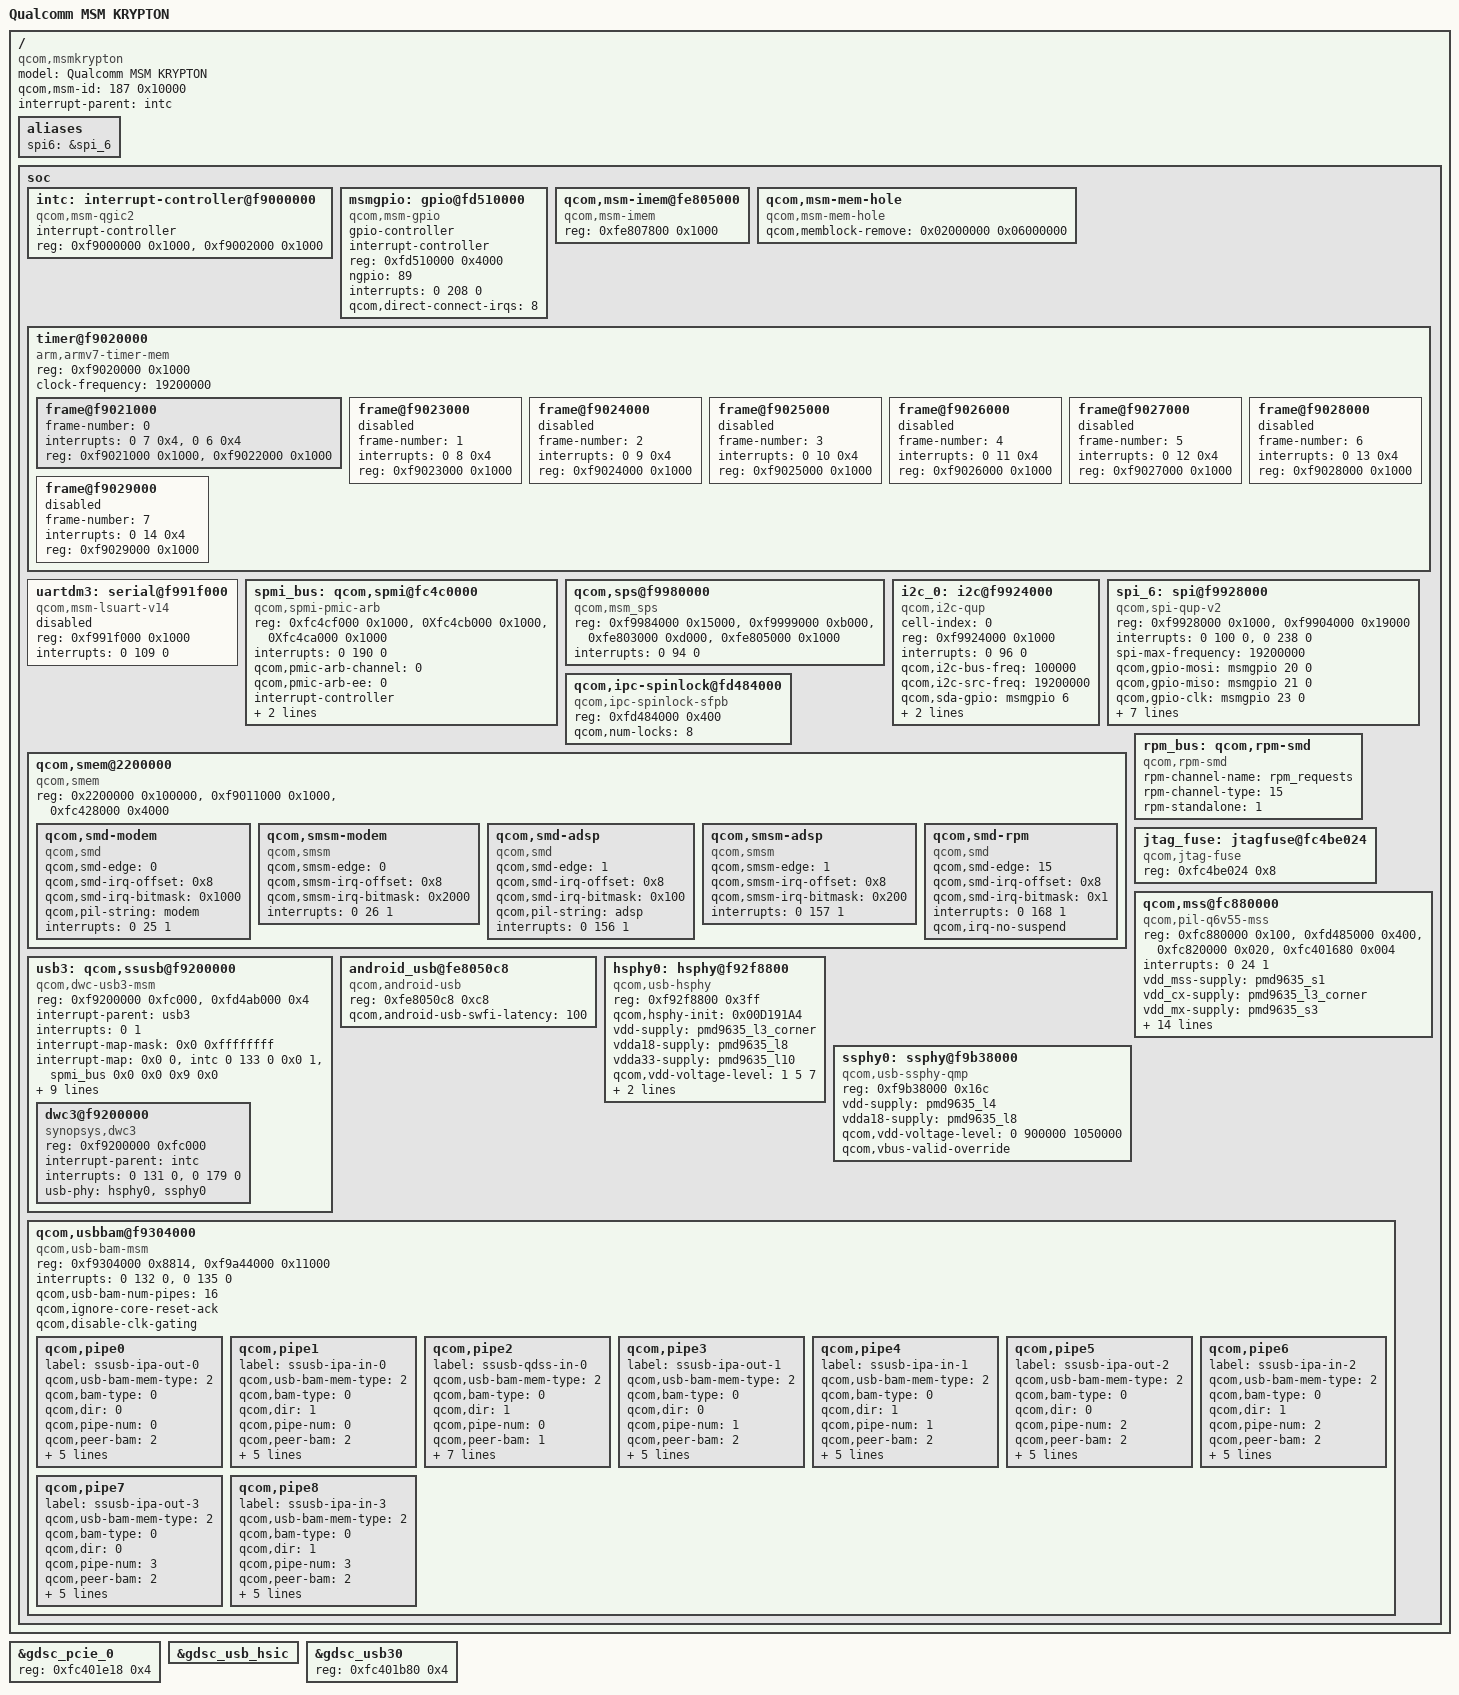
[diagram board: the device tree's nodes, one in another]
/* Copyright (c) 2013, The Linux Foundation. All rights reserved.
 *
 * This program is free software; you can redistribute it and/or modify
 * it under the terms of the GNU General Public License version 2 and
 * only version 2 as published by the Free Software Foundation.
 *
 * This program is distributed in the hope that it will be useful,
 * but WITHOUT ANY WARRANTY; without even the implied warranty of
 * MERCHANTABILITY or FITNESS FOR A PARTICULAR PURPOSE.  See the
 * GNU General Public License for more details.
 */

/include/ "skeleton.dtsi"

/ {
	model = "Qualcomm MSM KRYPTON";
	compatible = "qcom,msmkrypton";
	qcom,msm-id = <187 0x10000>;
	interrupt-parent = <&intc>;

	aliases {
		spi6 = &spi_6;
	};

	soc: soc { };
};

/include/ "msmkrypton-smp2p.dtsi"
/include/ "msmkrypton-coresight.dtsi"
/include/ "msm-gdsc.dtsi"

&soc {
	#address-cells = <1>;
	#size-cells = <1>;
	ranges;

	intc: interrupt-controller@f9000000 {
		compatible = "qcom,msm-qgic2";
		interrupt-controller;
		#interrupt-cells = <3>;
		reg = <0xf9000000 0x1000>,
		      <0xf9002000 0x1000>;
	};

	msmgpio: gpio@fd510000 {
		compatible = "qcom,msm-gpio";
		gpio-controller;
		#gpio-cells = <2>;
		interrupt-controller;
		#interrupt-cells = <2>;
		reg = <0xfd510000 0x4000>;
		ngpio = <89>;
		interrupts = <0 208 0>;
		qcom,direct-connect-irqs = <8>;
	};

	qcom,msm-imem@fe805000 {
		compatible = "qcom,msm-imem";
		reg = <0xfe807800 0x1000>; /* Address and size of IMEM */
	};

	qcom,msm-mem-hole {
		compatible = "qcom,msm-mem-hole";
		qcom,memblock-remove = <0x02000000 0x06000000>; /* Address and Size of Hole */
	};

	timer@f9020000 {
		#address-cells = <1>;
		#size-cells = <1>;
		ranges;
		compatible = "arm,armv7-timer-mem";
		reg = <0xf9020000 0x1000>;
		clock-frequency = <19200000>;

		frame@f9021000 {
			frame-number = <0>;
			interrupts = <0 7 0x4>,
				     <0 6 0x4>;
			reg = <0xf9021000 0x1000>,
			      <0xf9022000 0x1000>;
		};

		frame@f9023000 {
			frame-number = <1>;
			interrupts = <0 8 0x4>;
			reg = <0xf9023000 0x1000>;
			status = "disabled";
		};

		frame@f9024000 {
			frame-number = <2>;
			interrupts = <0 9 0x4>;
			reg = <0xf9024000 0x1000>;
			status = "disabled";
		};

		frame@f9025000 {
			frame-number = <3>;
			interrupts = <0 10 0x4>;
			reg = <0xf9025000 0x1000>;
			status = "disabled";
		};

		frame@f9026000 {
			frame-number = <4>;
			interrupts = <0 11 0x4>;
			reg = <0xf9026000 0x1000>;
			status = "disabled";
		};

		frame@f9027000 {
			frame-number = <5>;
			interrupts = <0 12 0x4>;
			reg = <0xf9027000 0x1000>;
			status = "disabled";
		};

		frame@f9028000 {
			frame-number = <6>;
			interrupts = <0 13 0x4>;
			reg = <0xf9028000 0x1000>;
			status = "disabled";
		};

		frame@f9029000 {
			frame-number = <7>;
			interrupts = <0 14 0x4>;
			reg = <0xf9029000 0x1000>;
			status = "disabled";
		};
	};

	uartdm3: serial@f991f000 {
		compatible = "qcom,msm-lsuart-v14";
		reg = <0xf991f000 0x1000>;
		interrupts = <0 109 0>;
		status = "disabled";
	};

	spmi_bus: qcom,spmi@fc4c0000 {
		compatible = "qcom,spmi-pmic-arb";
		reg = <0xfc4cf000 0x1000>,
		      <0Xfc4cb000 0x1000>,
		      <0Xfc4ca000 0x1000>;
		reg-names = "core", "intr", "cnfg";
		interrupts = <0 190 0>;
		qcom,pmic-arb-channel = <0>;
		qcom,pmic-arb-ee = <0>;
		#interrupt-cells = <3>;
		interrupt-controller;
		#address-cells = <1>;
		#size-cells = <0>;
		cell-index = <0>;
		qcom,not-wakeup; /* Needed until MPM is fully configured */
	};

	qcom,sps@f9980000 {
		compatible = "qcom,msm_sps";
		reg = <0xf9984000 0x15000>,
		      <0xf9999000 0xb000>,
		      <0xfe803000 0xd000>,
			  <0xfe805000 0x1000>;
		interrupts = <0 94 0>;
	};

	i2c_0: i2c@f9924000 { /* BLSP1 QUP2 */
		cell-index = <0>;
		compatible = "qcom,i2c-qup";
		#address-cells = <1>;
		#size-cells = <0>;
		reg-names = "qup_phys_addr";
		reg = <0xf9924000 0x1000>;
		interrupt-names = "qup_err_intr";
		interrupts = <0 96 0>;
		qcom,i2c-bus-freq = <100000>;
		qcom,i2c-src-freq = <19200000>;
		qcom,sda-gpio = <&msmgpio 6 0>;
		qcom,scl-gpio = <&msmgpio 7 0>;
		qcom,master-id = <86>;
	};

	spi_6: spi@f9928000 { /* BLSP1 QUP6 */
		compatible = "qcom,spi-qup-v2";
		#address-cells = <1>;
		#size-cells = <0>;
		reg-names = "spi_physical", "spi_bam_physical";
		reg = <0xf9928000 0x1000>,
		      <0xf9904000 0x19000>;
		interrupt-names = "spi_irq", "spi_bam_irq";
		interrupts = <0 100 0>, <0 238 0>;
		spi-max-frequency = <19200000>;

		qcom,gpio-mosi = <&msmgpio 20 0>;
		qcom,gpio-miso = <&msmgpio 21 0>;
		qcom,gpio-clk  = <&msmgpio 23 0>;
		qcom,gpio-cs0  = <&msmgpio 22 0>;

		qcom,infinite-mode = <0>;
		qcom,use-bam;
		qcom,ver-reg-exists;
		qcom,bam-consumer-pipe-index = <22>;
		qcom,bam-producer-pipe-index = <23>;
		qcom,master-id = <86>;
	};

	qcom,ipc-spinlock@fd484000 {
		compatible = "qcom,ipc-spinlock-sfpb";
		reg = <0xfd484000 0x400>;
		qcom,num-locks = <8>;
	};

	qcom,smem@2200000 {
		compatible = "qcom,smem";
		reg = <0x2200000 0x100000>,
			<0xf9011000 0x1000>,
			<0xfc428000 0x4000>;
		reg-names = "smem", "irq-reg-base", "aux-mem1";

		qcom,smd-modem {
			compatible = "qcom,smd";
			qcom,smd-edge = <0>;
			qcom,smd-irq-offset = <0x8>;
			qcom,smd-irq-bitmask = <0x1000>;
			qcom,pil-string = "modem";
			interrupts = <0 25 1>;
		};

		qcom,smsm-modem {
			compatible = "qcom,smsm";
			qcom,smsm-edge = <0>;
			qcom,smsm-irq-offset = <0x8>;
			qcom,smsm-irq-bitmask = <0x2000>;
			interrupts = <0 26 1>;
		};

		qcom,smd-adsp {
			compatible = "qcom,smd";
			qcom,smd-edge = <1>;
			qcom,smd-irq-offset = <0x8>;
			qcom,smd-irq-bitmask = <0x100>;
			qcom,pil-string = "adsp";
			interrupts = <0 156 1>;
		};

		qcom,smsm-adsp {
			compatible = "qcom,smsm";
			qcom,smsm-edge = <1>;
			qcom,smsm-irq-offset = <0x8>;
			qcom,smsm-irq-bitmask = <0x200>;
			interrupts = <0 157 1>;
		};

		qcom,smd-rpm {
			compatible = "qcom,smd";
			qcom,smd-edge = <15>;
			qcom,smd-irq-offset = <0x8>;
			qcom,smd-irq-bitmask = <0x1>;
			interrupts = <0 168 1>;
			qcom,irq-no-suspend;
		};
	};

	rpm_bus: qcom,rpm-smd {
		compatible = "qcom,rpm-smd";
		rpm-channel-name = "rpm_requests";
		rpm-channel-type = <15>; /* SMD_APPS_RPM */
		rpm-standalone = <1>;
	};

	jtag_fuse: jtagfuse@fc4be024 {
		compatible = "qcom,jtag-fuse";
		reg = <0xfc4be024 0x8>;
		reg-names = "fuse-base";
	};

	qcom,mss@fc880000 {
		compatible = "qcom,pil-q6v55-mss";
		reg = <0xfc880000 0x100>,
		      <0xfd485000 0x400>,
		      <0xfc820000 0x020>,
		      <0xfc401680 0x004>;
		reg-names = "qdsp6_base", "halt_base", "rmb_base",
			    "restart_reg";

		interrupts = <0 24 1>;
		vdd_mss-supply = <&pmd9635_s1>;
		vdd_cx-supply = <&pmd9635_l3_corner>;
		vdd_mx-supply = <&pmd9635_s3>;
		vdd_pll-supply = <&pmd9635_l7>;
		qcom,vdd_pll = <1800000>;

		qcom,firmware-name = "mba";
		qcom,pil-self-auth;

		/* GPIO inputs from mss */
		qcom,gpio-err-fatal = <&smp2pgpio_ssr_smp2p_1_in 0 0>;
		qcom,gpio-err-ready = <&smp2pgpio_ssr_smp2p_1_in 1 0>;
		qcom,gpio-proxy-unvote = <&smp2pgpio_ssr_smp2p_1_in 2 0>;
		qcom,gpio-stop-ack = <&smp2pgpio_ssr_smp2p_1_in 3 0>;

		/* GPIO output to mss */
		qcom,gpio-force-stop = <&smp2pgpio_ssr_smp2p_1_out 0 0>;
	};

	usb3: qcom,ssusb@f9200000 {
		compatible = "qcom,dwc-usb3-msm";
		reg = <0xf9200000 0xfc000>,
				<0xfd4ab000 0x4>;
		#address-cells = <1>;
		#size-cells = <1>;
		ranges;

		interrupt-parent = <&usb3>;
		interrupts = <0 1>;
		#interrupt-cells = <1>;
		interrupt-map-mask = <0x0 0xffffffff>;
		interrupt-map = <0x0 0 &intc 0 133 0
						0x0 1 &spmi_bus 0x0 0x0 0x9 0x0>;
		interrupt-names = "hs_phy_irq", "pmic_id_irq";

		USB3_GDSC-supply = <&gdsc_usb30>;
		qcom,dwc-usb3-msm-dbm-eps = <8>;
		qcom,otg-capability;
		qcom,dwc-hsphy-init = <0x00D191A4>;

		qcom,msm-bus,name = "usb3";
		qcom,msm-bus,num-cases = <2>;
		qcom,msm-bus,num-paths = <1>;
		qcom,msm-bus,vectors-KBps =
						<61 512 0 0>,
						<61 512 240000 960000>;

		dwc3@f9200000 {
				compatible = "synopsys,dwc3";
				reg = <0xf9200000 0xfc000>;
				interrupt-parent = <&intc>;
				interrupts = <0 131 0>, <0 179 0>;
				interrupt-names = "irq", "otg_irq";
				usb-phy = <&hsphy0>, <&ssphy0>;
		};
        };

	android_usb@fe8050c8 {
		reg = <0xfe8050c8 0xc8>;
		compatible = "qcom,android-usb";
		qcom,android-usb-swfi-latency = <100>;
	};

	hsphy0: hsphy@f92f8800 {
		compatible = "qcom,usb-hsphy";
		reg = <0xf92f8800 0x3ff>;
		qcom,hsphy-init = <0x00D191A4>;
		vdd-supply = <&pmd9635_l3_corner>;
		vdda18-supply = <&pmd9635_l8>;
		vdda33-supply = <&pmd9635_l10>;
		qcom,vdd-voltage-level = <1 5 7>;
		qcom,ext-vbus-id;
		qcom,vbus-valid-override;
	};

	ssphy0: ssphy@f9b38000 {
		compatible = "qcom,usb-ssphy-qmp";
		reg = <0xf9b38000 0x16c>;
		vdd-supply = <&pmd9635_l4>;
		vdda18-supply = <&pmd9635_l8>;
		qcom,vdd-voltage-level = <0 900000 1050000>;
		qcom,vbus-valid-override;
	};

	qcom,usbbam@f9304000 {
		compatible = "qcom,usb-bam-msm";
		reg = <0xf9304000 0x8814>,
		      <0xf9a44000 0x11000>;
		reg-names = "ssusb", "hsusb";
		interrupts = <0 132 0>,<0 135 0>;
		interrupt-names = "ssusb", "hsusb";
		qcom,usb-bam-num-pipes = <16>;
		qcom,ignore-core-reset-ack;
		qcom,disable-clk-gating;

		qcom,pipe0 {
			label = "ssusb-ipa-out-0";
			qcom,usb-bam-mem-type = <2>;
			qcom,bam-type = <0>;
			qcom,dir = <0>;
			qcom,pipe-num = <0>;
			qcom,peer-bam = <2>;
			qcom,src-bam-physical-address = <0xf9304000>;
			qcom,src-bam-pipe-index = <1>;
			qcom,data-fifo-size = <0x8000>;
			qcom,descriptor-fifo-size = <0x2000>;
			qcom,reset-bam-on-connect;
		};
		qcom,pipe1 {
			label = "ssusb-ipa-in-0";
			qcom,usb-bam-mem-type = <2>;
			qcom,bam-type = <0>;
			qcom,dir = <1>;
			qcom,pipe-num = <0>;
			qcom,peer-bam = <2>;
			qcom,dst-bam-physical-address = <0xf9304000>;
			qcom,dst-bam-pipe-index = <0>;
			qcom,data-fifo-size = <0x8000>;
			qcom,descriptor-fifo-size = <0x2000>;
			qcom,reset-bam-on-connect;
		};
		qcom,pipe2 {
			label = "ssusb-qdss-in-0";
			qcom,usb-bam-mem-type = <2>;
			qcom,bam-type = <0>;
			qcom,dir = <1>;
			qcom,pipe-num = <0>;
			qcom,peer-bam = <1>;
			qcom,src-bam-physical-address = <0xfc37C000>;
			qcom,src-bam-pipe-index = <0>;
			qcom,dst-bam-physical-address = <0xf9304000>;
			qcom,dst-bam-pipe-index = <2>;
			qcom,data-fifo-size = <0x700>;
			qcom,descriptor-fifo-size = <0x100>;
			qcom,reset-bam-on-connect;
		};
		qcom,pipe3 {
			label = "ssusb-ipa-out-1";
			qcom,usb-bam-mem-type = <2>;
			qcom,bam-type = <0>;
			qcom,dir = <0>;
			qcom,pipe-num = <1>;
			qcom,peer-bam = <2>;
			qcom,src-bam-physical-address = <0xf9304000>;
			qcom,src-bam-pipe-index = <3>;
			qcom,data-fifo-size = <0x8000>;
			qcom,descriptor-fifo-size = <0x2000>;
			qcom,reset-bam-on-connect;
		};
		qcom,pipe4 {
			label = "ssusb-ipa-in-1";
			qcom,usb-bam-mem-type = <2>;
			qcom,bam-type = <0>;
			qcom,dir = <1>;
			qcom,pipe-num = <1>;
			qcom,peer-bam = <2>;
			qcom,dst-bam-physical-address = <0xf9304000>;
			qcom,dst-bam-pipe-index = <2>;
			qcom,data-fifo-size = <0x8000>;
			qcom,descriptor-fifo-size = <0x2000>;
			qcom,reset-bam-on-connect;
		};
		qcom,pipe5 {
			label = "ssusb-ipa-out-2";
			qcom,usb-bam-mem-type = <2>;
			qcom,bam-type = <0>;
			qcom,dir = <0>;
			qcom,pipe-num = <2>;
			qcom,peer-bam = <2>;
			qcom,src-bam-physical-address = <0xf9304000>;
			qcom,src-bam-pipe-index = <5>;
			qcom,data-fifo-size = <0x8000>;
			qcom,descriptor-fifo-size = <0x2000>;
			qcom,reset-bam-on-connect;
		};
		qcom,pipe6 {
			label = "ssusb-ipa-in-2";
			qcom,usb-bam-mem-type = <2>;
			qcom,bam-type = <0>;
			qcom,dir = <1>;
			qcom,pipe-num = <2>;
			qcom,peer-bam = <2>;
			qcom,dst-bam-physical-address = <0xf9304000>;
			qcom,dst-bam-pipe-index = <4>;
			qcom,data-fifo-size = <0x8000>;
			qcom,descriptor-fifo-size = <0x2000>;
			qcom,reset-bam-on-connect;
		};
		qcom,pipe7  {
			label = "ssusb-ipa-out-3";
			qcom,usb-bam-mem-type = <2>;
			qcom,bam-type = <0>;
			qcom,dir = <0>;
			qcom,pipe-num = <3>;
			qcom,peer-bam = <2>;
			qcom,src-bam-physical-address = <0xf9304000>;
			qcom,src-bam-pipe-index = <6>;
			qcom,data-fifo-size = <0x8000>;
			qcom,descriptor-fifo-size = <0x2000>;
			qcom,reset-bam-on-connect;
		};
		qcom,pipe8  {
			label = "ssusb-ipa-in-3";
			qcom,usb-bam-mem-type = <2>;
			qcom,bam-type = <0>;
			qcom,dir = <1>;
			qcom,pipe-num = <3>;
			qcom,peer-bam = <2>;
			qcom,dst-bam-physical-address = <0xf9304000>;
			qcom,dst-bam-pipe-index = <7>;
			qcom,data-fifo-size = <0x8000>;
			qcom,descriptor-fifo-size = <0x2000>;
			qcom,reset-bam-on-connect;
		};
	};
};

&gdsc_pcie_0 {
	status = "ok";
	reg = <0xfc401e18 0x4>;
};

&gdsc_usb_hsic {
	status = "ok";
};

&gdsc_usb30 {
	status = "ok";
	reg = <0xfc401b80 0x4>;
};

/include/ "msm-pmd9635.dtsi"
/include/ "msmkrypton-regulator.dtsi"
